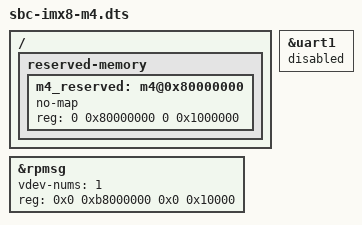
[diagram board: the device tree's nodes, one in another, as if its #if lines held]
/*
 * Copyright (C) 2018 CopuLab Ltd.
 *
 * This program is free software; you can redistribute it and/or
 * modify it under the terms of the GNU General Public License
 * as published by the Free Software Foundation; either version 2
 * of the License, or (at your option) any later version.
 *
 * This program is distributed in the hope that it will be useful,
 * but WITHOUT ANY WARRANTY; without even the implied warranty of
 * MERCHANTABILITY or FITNESS FOR A PARTICULAR PURPOSE.  See the
 * GNU General Public License for more details.
 */

#include "sbc-imx8.dts"

#ifdef DDR_M4_SUPPORT
/ {
	reserved-memory {
		#address-cells = <2>;
		#size-cells = <2>;
		ranges;

		m4_reserved: m4@0x80000000 {
			no-map;
			reg = <0 0x80000000 0 0x1000000>;
		};

	};
};
#endif

&rpmsg{
	/*
	 * 64K for one rpmsg instance:
	 * --0xb8000000~0xb800ffff: pingpong
	 */
	vdev-nums = <1>;
	reg = <0x0 0xb8000000 0x0 0x10000>;
	status = "okay";
};

&uart1 {
	status = "disabled";
};
